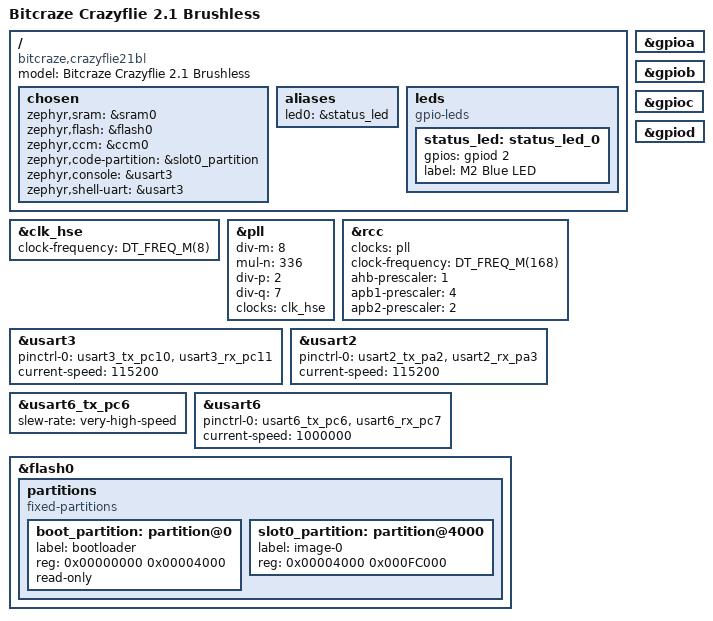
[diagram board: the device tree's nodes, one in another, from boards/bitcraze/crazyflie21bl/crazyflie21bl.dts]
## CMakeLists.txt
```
cmake_minimum_required(VERSION 3.20.0)

# Out-of-tree board definitions (crazyflie21bl).  Must be set before find_package.
list(APPEND BOARD_ROOT ${CMAKE_CURRENT_SOURCE_DIR})

# tapestry-os/dts/bindings/ holds custom DTS bindings (e.g. bitcraze,cf21-motors).
list(APPEND DTS_ROOT ${CMAKE_CURRENT_SOURCE_DIR}/../tapestry-os)

if("${BOARD}" STREQUAL "bbc_microbit_v2")
    set(DTC_OVERLAY_FILE
        ${CMAKE_CURRENT_SOURCE_DIR}/../tapestry-os/boards/bbc_microbit_v2/bbc_microbit_v2.overlay)
elseif("${BOARD}" STREQUAL "crazyflie21bl")
    set(DTC_OVERLAY_FILE
        ${CMAKE_CURRENT_SOURCE_DIR}/../tapestry-os/boards/crazyflie21bl/crazyflie21bl.overlay)
elseif("${BOARD}" STREQUAL "apollo510_evb")
    set(DTC_OVERLAY_FILE
        ${CMAKE_CURRENT_SOURCE_DIR}/../tapestry-os/boards/apollo510_evb/apollo510_evb.overlay)
elseif("${BOARD}" STREQUAL "apollo330mP_evb")
    set(DTC_OVERLAY_FILE
        ${CMAKE_CURRENT_SOURCE_DIR}/../tapestry-os/boards/apollo330mP_evb/apollo330mP_evb.overlay)
elseif("${BOARD}" STREQUAL "ek_ra8d1")
    # Adds only a tapestry,gossip-uart chosen node pointing at UART3, so the
    # RA8D1 can join a wired gossip bus.  Inert in the default Ethernet/UDP
    # build — nothing reads the node unless transceiver_uart.c is compiled in.
    set(DTC_OVERLAY_FILE
        ${CMAKE_CURRENT_SOURCE_DIR}/../tapestry-os/boards/ek_ra8d1/ek_ra8d1.overlay)
endif()

# Apollo510 EVB: make `west flash` reliable.
#
# The Apollo510 is a secure part whose bootloader must run to completion after
# reset.  J-Link's default reset races it: the runner's generated script goes
# `r` straight into `loadfile` with no `halt` between, so the flash loader can
# start while the bootloader is still running.  Measured on hardware
# 2026-08-25: 2 failures in 4 runs, each aborting after "Programming flash
# [100%] Done" and leaving a HALF-WRITTEN image that boots and then hard-faults
# — a failure that reads convincingly as a firmware bug.
#
# Reset type 2 fixes it: 5 clean runs versus 2 failures in 4 with the default
# reset.  Under the old rate a clean run of 5 had roughly a 3% chance, so the
# improvement is real — though 5 trials cannot prove a race never fires.  west
# exits non-zero on failure, so a bad flash is always visible at the shell.
# `--speed 500` was tried and did not help.
#
# Injected via the BOARD_RUNNER_ARGS_<runner> cache variable, which
# board_finalize_runner_args() appends last of all (so it wins over the board's
# own args).  The documented app_set_runner_args() macro hook was tried first
# and did not take effect on Zephyr 4.4.0-rc1 — board_finalize_runner_args()
# demonstrably ran (its --dt-flash=y reached runners.yaml) but did not see the
# macro.  Unexplained; the cache variable is read by the same function two
# lines later and does work.
if("${BOARD}" STREQUAL "apollo510_evb")
    set(BOARD_RUNNER_ARGS_jlink "--reset-type=2" CACHE INTERNAL
        "Ambiq secure-bootloader-safe JLink reset")
endif()
# apollo330mP_evb is excluded: Ambiq's bundled jlink.py runner has no
# --reset-type option and errors on it.

find_package(Zephyr REQUIRED HINTS $ENV{ZEPHYR_BASE})
project(tapestry_hw_element)

set(TAPESTRY_OS_ROOT      ${CMAKE_CURRENT_SOURCE_DIR}/../tapestry-os)
set(TAPESTRY_OS_CSM       ${TAPESTRY_OS_ROOT}/subsys/csm)
set(TAPESTRY_OS_SCR       ${TAPESTRY_OS_ROOT}/subsys/scr)
set(TAPESTRY_OS_TRANSPORT ${TAPESTRY_OS_ROOT}/subsys/transport)
set(TAPESTRY_OS_BSE       ${TAPESTRY_OS_ROOT}/subsys/bse)
set(TAPESTRY_OS_CHOREO    ${TAPESTRY_OS_ROOT}/subsys/choreo)
set(TAPESTRY_OS_RUNTIME   ${TAPESTRY_OS_ROOT}/subsys/runtime)
set(TAPESTRY_OS_BOARDS    ${TAPESTRY_OS_ROOT}/boards)
set(TAPESTRY_SDK          ${CMAKE_CURRENT_SOURCE_DIR}/../sdk)

# Core L2 runtime + L4/L5 stack + L6 BSE stub + L7 SDK stub + transport.
target_sources(app PRIVATE
    src/main.c
    ${TAPESTRY_OS_RUNTIME}/runtime.c
    ${TAPESTRY_OS_RUNTIME}/power.c
    ${TAPESTRY_OS_CSM}/world_model.c
    ${TAPESTRY_OS_CSM}/facts.c
    ${TAPESTRY_OS_SCR}/scr.c
    ${TAPESTRY_OS_BSE}/bse.c
    ${TAPESTRY_OS_CHOREO}/choreo.c
    ${TAPESTRY_OS_TRANSPORT}/transport.c
    ${TAPESTRY_OS_TRANSPORT}/gossip.c
)

# UDP transceiver + network bring-up — ESP32 and RA8D1 only.
if(CONFIG_NETWORKING)
    target_sources(app PRIVATE
        ${TAPESTRY_OS_TRANSPORT}/transceiver_udp.c
        ${TAPESTRY_OS_TRANSPORT}/net_init.c
    )
endif()

# BLE transceiver — ESP32 (bridge) and micro:bit.
if(CONFIG_BT)
    target_sources(app PRIVATE ${TAPESTRY_OS_TRANSPORT}/transceiver_ble.c)
endif()

# Stub transceiver backends (compiled when the matching Kconfig symbol is set
# by a board overlay; not active in any current build).
if(CONFIG_TAPESTRY_TRANSCEIVER_ACOUSTIC)
    target_sources(app PRIVATE ${TAPESTRY_OS_TRANSPORT}/transceiver_acoustic.c)
endif()
if(CONFIG_TAPESTRY_TRANSCEIVER_OPTICAL)
    target_sources(app PRIVATE ${TAPESTRY_OS_TRANSPORT}/transceiver_optical.c)
endif()
if(CONFIG_TAPESTRY_TRANSCEIVER_CHEMICAL)
    target_sources(app PRIVATE ${TAPESTRY_OS_TRANSPORT}/transceiver_chemical.c)
endif()
if(CONFIG_TAPESTRY_TRANSCEIVER_SYSLINK)
    target_sources(app PRIVATE ${TAPESTRY_OS_TRANSPORT}/transceiver_syslink_p2p.c)
endif()

# Wired serial gossip bus — the only medium available to radio-less boards
# (Apollo510 EVB).  Board-agnostic: needs a spare interrupt-driven UART and a
# `tapestry,gossip-uart` chosen node in the board overlay.
if(CONFIG_TAPESTRY_TRANSCEIVER_UART)
    target_sources(app PRIVATE ${TAPESTRY_OS_TRANSPORT}/transceiver_uart.c)
endif()

# CF2.1 early IWDG kick — must be compiled unconditionally so it runs even in
# minimal blink-test builds (CONFIG_PWM=n).  The Bitcraze bootloader arms the
# IWDG before jumping to us; without this, the watchdog fires within ~100-353ms.
#
# CF2.1 CRTP log backend — sends Zephyr LOG_* output as syslink console packets
# over USART6 to the nRF51 co-processor; crazyflie_console.py receives them via radio.
# Compiled only when CONFIG_LOG=y (i.e. the log subsystem is present).
# cf21bl_syslink_tx.c (the shared USART6 TX mutex) is compiled unconditionally
# alongside it so any combination of USART6 writers (console, PM, syslink P2P
# transport) can be linked together safely.
if("${BOARD}" STREQUAL "crazyflie21bl")
    target_sources(app PRIVATE
        ${TAPESTRY_OS_BOARDS}/crazyflie21bl/cf21bl_iwdg.c
        ${TAPESTRY_OS_BOARDS}/crazyflie21bl/cf21bl_syslink_tx.c)
    if(CONFIG_LOG)
        target_sources(app PRIVATE ${TAPESTRY_OS_BOARDS}/crazyflie21bl/cf21bl_crtp_log.c)
    endif()
endif()

# Substrate: CF2.1 brushless on crazyflie21bl, Cutebot on micro:bit,
# LED/button status output on apollo510_evb, null elsewhere.
#
# Boards with a substrate of their own are matched by NAME before the
# CONFIG_* heuristics below.  Those heuristics infer a substrate from which
# buses a board happens to enable, which is only sound while every such board
# has exactly one plausible substrate — apollo510_evb breaks that (it has no
# actuators at all, and enabling I2C or PWM on it for an unrelated reason
# would silently select the Cutebot or Crazyflie driver).
#
# Within the heuristics, PWM must be checked before I2C: the CF21 stabilizer
# uses both (PWM for motors, I2C for the BMI088 IMU), so checking I2C first
# would wrongly select the Cutebot path.
if("${BOARD}" STREQUAL "apollo510_evb" OR "${BOARD}" STREQUAL "apollo330mP_evb")
    # Shared LED/button substrate — entirely devicetree-driven (led0..led2, sw0),
    # so one implementation serves both Ambiq EVBs.
    target_sources(app PRIVATE
        ${TAPESTRY_OS_BOARDS}/ambiq_common/substrate_ambiq_evb.c)
    if("${BOARD}" STREQUAL "apollo510_evb" AND CONFIG_TAPESTRY_AP510_PIN_FINDER)
        target_sources(app PRIVATE
            ${TAPESTRY_OS_BOARDS}/apollo510_evb/ap510_pin_finder.c)
    endif()
elseif(CONFIG_PWM)
    target_sources(app PRIVATE
        ${TAPESTRY_OS_BOARDS}/crazyflie21bl/substrate_crazyflie21bl.c
        ${TAPESTRY_OS_BOARDS}/crazyflie21bl/crazyflie21bl.c
    )
    if(CONFIG_CF21BL_STABILIZER)
        target_sources(app PRIVATE
            ${TAPESTRY_OS_BOARDS}/crazyflie21bl/cf21bl_stabilizer.c
            ${TAPESTRY_OS_BOARDS}/crazyflie21bl/cf21bl_imu.c
        )
    endif()
elseif(CONFIG_I2C)
    target_sources(app PRIVATE
        ${TAPESTRY_OS_BOARDS}/bbc_microbit_v2/substrate_cutebot.c
        ${TAPESTRY_OS_BOARDS}/bbc_microbit_v2/cutebot.c
    )
else()
    target_sources(app PRIVATE ${TAPESTRY_OS_BOARDS}/substrate_null.c)
endif()

target_include_directories(app PRIVATE
    ${TAPESTRY_OS_ROOT}/include                    # <tapestry/csm.h>, <tapestry/scr.h>, <tapestry/transport.h>, <tapestry/substrate.h>, <tapestry/bse.h>, <tapestry/runtime.h>
    ${TAPESTRY_SDK}/include                        # <tapestry/choreo.h>
    ${TAPESTRY_OS_CSM}                             # world_model.c; types via <tapestry/csm.h>
    ${TAPESTRY_OS_SCR}                             # scr.h internals
    ${TAPESTRY_OS_RUNTIME}                         # power.h (internal)
    ${TAPESTRY_OS_TRANSPORT}                       # gossip.h, transceiver_ble.h, transceiver_udp.h, net_init.h
    ${TAPESTRY_OS_BOARDS}/bbc_microbit_v2          # cutebot.h
    ${TAPESTRY_OS_BOARDS}/crazyflie21bl             # crazyflie21bl_mix.h, crazyflie21bl.h
    src
)

target_link_libraries(app PRIVATE m)
```

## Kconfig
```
# Kconfig — Tapestry hardware element configuration
#
# Values are baked into the firmware at build time via CONFIG_* macros.
# WiFi credentials are sensitive: supply them via a gitignored wifi.conf
# passed with  west build --extra-conf wifi.conf
# (--extra-conf resolves relative to the application directory, not the CWD)

# Pull in all Zephyr Kconfig symbols (NETWORKING, WIFI, LOG, …).
# Without this every standard symbol appears "undefined".
source "Kconfig.zephyr"
rsource "../tapestry-os/subsys/runtime/Kconfig"
rsource "../tapestry-os/subsys/transport/Kconfig"
rsource "../tapestry-os/boards/crazyflie21bl/Kconfig"
rsource "../tapestry-os/boards/apollo510_evb/Kconfig"

config TAPESTRY_ELEMENT_ID
	int "Element ID [0..4]"
	range 0 4
	default 0
	help
	  Unique identity for this physical element. Determines leader
	  election priority (lowest ID wins) and gossip source tagging.
	  Set to 0 for ESP-WROVER-KIT, 1 for EK-RA8D1.

config TAPESTRY_GOSSIP_PORT
	int "UDP port for gossip broadcast/receive"
	default 5000

config TAPESTRY_GOSSIP_BCAST
	string "Gossip broadcast address"
	default "255.255.255.255"
	help
	  Destination address for gossip UDP datagrams.  The limited broadcast
	  (255.255.255.255) is NOT forwarded between WiFi and Ethernet segments
	  by most home routers.  Set this to the subnet directed broadcast
	  (e.g. 192.168.86.255 for a 192.168.86.0/24 network) so that gossip
	  crosses the WiFi/Ethernet boundary.


config TAPESTRY_METRIC_PORT
	int "UDP port for telemetry metrics (unicast to collector)"
	default 5100

config TAPESTRY_ORCH_IP
	string "Telemetry collector IP address"
	default ""
	help
	  IPv4 address of the machine running telemetry/collect.py.
	  Metrics are silently dropped when this is left empty.

config TAPESTRY_QUORUM_MIN
	int "SCR minimum fresh peers for DEGRADED state"
	range 0 4
	default 1

config TAPESTRY_QUORUM_TARGET
	int "SCR minimum fresh peers for HEALTHY state"
	range 0 4
	default 1

if WIFI

config TAPESTRY_WIFI_SSID
	string "WiFi SSID"
	default ""

config TAPESTRY_WIFI_PSK
	string "WiFi pre-shared key (WPA2)"
	default ""

endif # WIFI
```

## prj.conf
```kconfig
# ── Stack / heap ──────────────────────────────────────────────────────────────
CONFIG_MAIN_STACK_SIZE=8192

# ── Floating point ────────────────────────────────────────────────────────────
# Needed explicitly for ESP32 and micro:bit; harmless for RA8D1.
CONFIG_FPU=y

# ── Logging ───────────────────────────────────────────────────────────────────
CONFIG_LOG=y
CONFIG_LOG_DEFAULT_LEVEL=3
CONFIG_PRINTK=y

# Board-specific configs (networking, BLE, I2C) live in boards/<board>.conf
# so each target only pulls in what its hardware supports.
```

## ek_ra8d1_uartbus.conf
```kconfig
# Wired-gossip-bus variant for the Renesas EK-RA8D1.
#
# Overrides the board's default Ethernet/UDP transport (boards/ek_ra8d1.conf)
# so the RA8D1 gossips over a shared serial bus instead — letting it pair
# directly with the radio-less Apollo510 EVB with no host, no LAN, and no
# collector.  A genuinely heterogeneous swarm: Renesas Cortex-M85 talking to
# Ambiq Cortex-M55 over two wires.
#
# Build (from the workspace root):
#   west build -b ek_ra8d1 \
#       --build-dir tapestry/tapestry-scr-hw/build/ra8d1-e1 \
#       tapestry/tapestry-scr-hw \
#       --extra-conf ek_ra8d1_uartbus.conf
#
# The --extra-conf path is resolved relative to the APPLICATION directory
# (tapestry-scr-hw), not the shell CWD — hence the bare filename.
#
# Element ID comes from boards/ek_ra8d1.conf, which already sets 1 — pairing
# with the Apollo510's default of 0.
#
# EXPECTED: this build prints a handful of Kconfig warnings about NET_* symbols
# having unmet dependencies.  They come from the networking block in
# boards/ek_ra8d1.conf, which Zephyr merges before this file and which cannot
# be made conditional.  Harmless — the symbols below win.

# ── Networking OFF ────────────────────────────────────────────────────────────
# Not merely unused: net_connect() ends in k_sem_take(&ip_acquired, K_FOREVER),
# so with networking enabled and no DHCP lease the element blocks forever in
# transport_init() and never reaches its main loop.  It must be off for a
# cable-free bus test.
#
# Turning networking off also switches telemetry from UDP-to-collector back to
# METRIC CSV lines on the console, which is what we want on the bench — and
# matches what the Apollo510 prints.
CONFIG_NETWORKING=n
CONFIG_NET_SOCKETS=n
CONFIG_NET_UDP=n
CONFIG_NET_IPV4=n
CONFIG_NET_DHCPV4=n
CONFIG_NET_L2_ETHERNET=n
CONFIG_NET_ARP=n

# ── Gossip transport: wired serial bus ────────────────────────────────────────
# UART3 (SCI3) is already enabled at 115200 by the stock board DTS; the
# Tapestry overlay only adds the tapestry,gossip-uart chosen node.
CONFIG_SERIAL=y
CONFIG_UART_INTERRUPT_DRIVEN=y
CONFIG_TAPESTRY_TRANSCEIVER_UART=y

# ── Hardware identity ─────────────────────────────────────────────────────────
CONFIG_HWINFO=y
```

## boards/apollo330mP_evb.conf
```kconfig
# Board overlay for the Ambiq Apollo330M Plus EVB (Apollo330P / Cortex-M55)
#
# Unlike the Apollo510 EVB this part has an on-die BLE controller reached over
# an HCI IPC channel (zephyr,bt-hci = &bt_hci_ipc0 in the board DTS), so it can
# gossip over BLE, over the wired serial bus, or both at once.  Both are
# enabled here: the wired bus pairs it with the Apollo510 EVB, and BLE pairs it
# with any Tapestry BLE element (micro:bit, ESP32).
#
# This board lives in Ambiq's Zephyr distribution, not upstream Zephyr — see
# tapestry-os/boards/apollo330mP_evb/README.md for the workspace.
#
# Build (from the workspace root):
#   west build -b apollo330mP_evb \
#       --build-dir tapestry/tapestry-scr-hw/build/ap330-e1 \
#       tapestry/tapestry-scr-hw -- -DCONFIG_TAPESTRY_ELEMENT_ID=1

# ── Floating point ────────────────────────────────────────────────────────────
CONFIG_FPU=y
CONFIG_FPU_SHARING=y

# ── Gossip transport: wired serial bus ────────────────────────────────────────
# UART1 is brought up as the bus by the Tapestry overlay, which also sets the
# tapestry,gossip-uart chosen node the transceiver reads.
CONFIG_SERIAL=y
CONFIG_UART_INTERRUPT_DRIVEN=y
CONFIG_TAPESTRY_TRANSCEIVER_UART=y

# ── Gossip transport: BLE ─────────────────────────────────────────────────────
# transceiver_ble.c registers alongside the wired bus; gossip_drain merges
# frames from both.  Comment this block out for a wired-only element.
CONFIG_BT=y
CONFIG_BT_OBSERVER=y
CONFIG_BT_BROADCASTER=y
# Peers on current main (micro:bit, ESP32) advertise the gossip frame with
# extended advertising; the scanner only receives those reports with this on.
CONFIG_BT_EXT_ADV=y
# Two advertising sets: state gossip and shared facts (transceiver_ble.c).
CONFIG_BT_EXT_ADV_MAX_ADV_SET=2
CONFIG_BT_DEVICE_NAME="tapestry-ap330"
CONFIG_BT_RX_STACK_SIZE=4096
CONFIG_SYSTEM_WORKQUEUE_STACK_SIZE=4096

# ── Hardware identity ─────────────────────────────────────────────────────────
CONFIG_HWINFO=y

# ── GPIO (LEDs + buttons for the L1 substrate) ────────────────────────────────
CONFIG_GPIO=y

# ── Element identity ──────────────────────────────────────────────────────────
# Override at build time with: -- -DCONFIG_TAPESTRY_ELEMENT_ID=N
# Defaults to 1 so it pairs with the Apollo510 EVB's default of 0.
CONFIG_TAPESTRY_ELEMENT_ID=1
```

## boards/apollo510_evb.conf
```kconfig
# Board overlay for the Ambiq Apollo510 EVB (Apollo510 / Cortex-M55)
# Radio-less swarm element: gossip over a wired serial bus, status on the
# three on-board LEDs, telemetry as METRIC CSV lines over the UART0 console.
#
# Build (from the workspace root):
#   west build -b apollo510_evb \
#       --build-dir tapestry/tapestry-scr-hw/build/ap510-e0 \
#       tapestry/tapestry-scr-hw -- -DCONFIG_TAPESTRY_ELEMENT_ID=0
#   west flash --build-dir tapestry/tapestry-scr-hw/build/ap510-e0
#
# Console: UART0, 115200 8N1, on the EVB's J-Link USB VCOM port.
#   minicom -D /dev/ttyACM0 -b 115200
#
# See tapestry-os/boards/apollo510_evb/README.md for bus wiring.

# ── Floating point ────────────────────────────────────────────────────────────
# The apollo5x SoC Kconfig selects CPU_HAS_FPU but does not turn CONFIG_FPU on.
# FPU_SHARING saves/restores FPU registers on context switches — required
# because float-touching code runs in main, the system workqueue, and the
# gossip stats work handler.
CONFIG_FPU=y
CONFIG_FPU_SHARING=y

# ── Gossip transport: wired serial bus ────────────────────────────────────────
# The Apollo510 has no radio on-die, so elements gossip over a shared UART
# bus.  UART2 is brought up as that bus by the Tapestry overlay
# (tapestry-os/boards/apollo510_evb/apollo510_evb.overlay), which also sets
# the `tapestry,gossip-uart` chosen node the transceiver reads.
#
# CONFIG_UART_INTERRUPT_DRIVEN is already set by the board's own defconfig.
CONFIG_SERIAL=y
CONFIG_UART_INTERRUPT_DRIVEN=y
CONFIG_TAPESTRY_TRANSCEIVER_UART=y

# ── Hardware identity ─────────────────────────────────────────────────────────
# Feeds the auto-ID nonce (CHIPID0/CHIPID1/trim revision via hwinfo_ambiq).
# Not required by this element — it takes its ID from Kconfig below — but
# cheap, and applications that call transport_negotiate_id() need it.
CONFIG_HWINFO=y

# ── GPIO (LEDs + buttons for the L1 substrate) ────────────────────────────────
CONFIG_GPIO=y

# ── Element identity ──────────────────────────────────────────────────────────
# Override at build time with: -- -DCONFIG_TAPESTRY_ELEMENT_ID=N
CONFIG_TAPESTRY_ELEMENT_ID=0

# ── Power management ──────────────────────────────────────────────────────────
# The board defconfig enables CONFIG_PM / PM_DEVICE / PM_DEVICE_RUNTIME and the
# SoC devicetree offers suspend-to-idle and suspend-to-ram.  Left on, and
# CONFIRMED on hardware 2026-08-25: transceiver_uart.c takes a pm_policy lock on
# PM_STATE_SUSPEND_TO_RAM at init so the gossip UART keeps its clock between
# cycles, while the shallower idle state stays available.  Loopback gossip runs
# clean with PM enabled — no special build flag is needed.
#
# If gossip RX ever goes lossy on a larger bus, CONFIG_PM=n is still the first
# bisect: it rules the policy lock in or out in one build.
```

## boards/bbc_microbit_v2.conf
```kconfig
# Board overlay for BBC micro:bit V2 (nRF52833 / Cortex-M4F)
# BLE swarm element with Cutebot Mini motor and LED output.
#
# No networking stack — gossip travels over BLE advertising instead.
# Telemetry is emitted as METRIC CSV lines over USB serial (115200 baud).
#
# The nRF52833 has a hardware FPU but Zephyr does not enable it by default.
# FPU_SHARING saves/restores FPU registers on context switches.

# ── Floating point ────────────────────────────────────────────────────────────
CONFIG_FPU=y
CONFIG_FPU_SHARING=y

# ── Bluetooth ─────────────────────────────────────────────────────────────────
# CONFIG_BT_EXT_ADV: required since the gossip frame (wire.h v3, 42 bytes)
# no longer fits legacy advertising's 31-byte payload — see
# transceiver_ble.c's header comment.
CONFIG_BT=y
CONFIG_BT_OBSERVER=y
CONFIG_BT_BROADCASTER=y
CONFIG_BT_EXT_ADV=y

# Controller advertising/scan BUFFERS are separate knobs from the
# extended-advertising feature itself and both default to 31 (the legacy
# payload size).  Left at the default, bt_le_ext_adv_set_data() fails -EDOM
# for every 48-byte wire.h v3 frame and no gossip is ever transmitted — the
# advertiser still starts cleanly, so the only symptom is that every element
# sees zero peers.  See examples/cutebot-formation/boards/bbc_microbit_v2.conf
# for the full write-up (2026-08-24).
CONFIG_BT_CTLR_ADV_DATA_LEN_MAX=64
CONFIG_BT_CTLR_SCAN_DATA_LEN_MAX=64
# Two advertising sets: state gossip and shared facts (transceiver_ble.c).
CONFIG_BT_EXT_ADV_MAX_ADV_SET=2
CONFIG_BT_DEVICE_NAME="tapestry"
CONFIG_BT_RX_STACK_SIZE=4096
CONFIG_SYSTEM_WORKQUEUE_STACK_SIZE=4096

# ── I2C (Cutebot) ─────────────────────────────────────────────────────────────
CONFIG_I2C=y
CONFIG_I2C_GPIO=y

# ── Element identity ──────────────────────────────────────────────────────────
# Override at build time with: -- -DCONFIG_TAPESTRY_ELEMENT_ID=N
CONFIG_TAPESTRY_ELEMENT_ID=0
```

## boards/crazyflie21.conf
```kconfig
# Board overlay for Bitcraze Crazyflie 2.1 brushless (STM32F405 / Cortex-M4F)
# BLE swarm element with brushless ESC output via TIM2 PWM.
#
# Build:
#   west build -b crazyflie21 tapestry/tapestry-scr-hw
#
# The Crazyflie 2.1 has an nRF51822 radio co-processor connected over UART.
# Full BLE gossip transport requires a UART-to-BLE bridge driver; that work
# is deferred until the board DTS is finalised.  The transport stubs compile
# and link cleanly; gossip simply produces no packets until the bridge lands.

# ── Floating point ────────────────────────────────────────────────────────────
CONFIG_FPU=y
CONFIG_FPU_SHARING=y

# ── PWM (brushless motor ESCs via TIM2) ───────────────────────────────────────
CONFIG_PWM=y

# ── Bluetooth (nRF51822 co-processor via USART6 HCI) ─────────────────────────
#
# PREREQUISITE: reflash the nRF51822 with HCI firmware before enabling.
# The factory radio firmware is not HCI-compatible.
#
# Once nRF51 runs HCI firmware, uncomment all lines below and rebuild.
# The USART6 node (PC6/PC7, 1 Mbps) is already enabled in the overlay.
#
# CONFIG_BT=y
# CONFIG_BT_HCI_UART=y
# CONFIG_BT_OBSERVER=y
# CONFIG_BT_BROADCASTER=y
# CONFIG_BT_DEVICE_NAME="tapestry-cf21"
# CONFIG_BT_RX_STACK_SIZE=4096
# CONFIG_SYSTEM_WORKQUEUE_STACK_SIZE=4096

# ── Element identity ──────────────────────────────────────────────────────────
# Override at build time with: -- -DCONFIG_TAPESTRY_ELEMENT_ID=N
CONFIG_TAPESTRY_ELEMENT_ID=0
```

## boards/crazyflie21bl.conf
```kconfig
# Board overlay for Bitcraze Crazyflie 2.1 brushless (STM32F405 / Cortex-M4F)
# BLE swarm element with brushless ESC output via TIM2 PWM.
#
# Build:
#   west build -b crazyflie21bl tapestry/tapestry-scr-hw -- -DCONFIG_PWM=n
#
# Console: USART3 on PC10 (TX) / PC11 (RX), 115200 baud.
# Connect a 3.3 V USB-serial adapter: white (RX) → PC10, green (TX) → PC11, GND.
# On Linux: minicom -D /dev/ttyUSB0 -b 115200

# ── Floating point ────────────────────────────────────────────────────────────
CONFIG_FPU=y
CONFIG_FPU_SHARING=y


# ── PWM (brushless motor ESCs via TIM2) ───────────────────────────────────────
CONFIG_PWM=y

# ── Bluetooth (nRF51822 co-processor via USART6 HCI) ─────────────────────────
#
# PREREQUISITE: reflash the nRF51822 with HCI firmware before enabling.
# The factory radio firmware is not HCI-compatible.
#
# Once nRF51 runs HCI firmware, uncomment all lines below and rebuild.
# The USART6 node (PC6/PC7, 1 Mbps) is already enabled in the overlay.
#
# CONFIG_BT=y
# CONFIG_BT_HCI_UART=y
# CONFIG_BT_OBSERVER=y
# CONFIG_BT_BROADCASTER=y
# CONFIG_BT_DEVICE_NAME="tapestry-cf21"
# CONFIG_BT_RX_STACK_SIZE=4096
# CONFIG_SYSTEM_WORKQUEUE_STACK_SIZE=4096

# ── Element identity ──────────────────────────────────────────────────────────
# Override at build time with: -- -DCONFIG_TAPESTRY_ELEMENT_ID=N
CONFIG_TAPESTRY_ELEMENT_ID=0

# Logging — required for cf21bl_crtp_log.c to be compiled and activated.
CONFIG_LOG=y
CONFIG_LOG_BACKEND_SHOW_COLOR=n

# USB CDC ACM console: attempted, blocked by what looked like a PLL_Q clock
# issue. Likely same root cause as the APB1/USART3 baud mismatch — &clk_hse
# in the DTS assumed a 40 MHz TCXO, but the stock firmware (HSE_VALUE=8000000,
# PLL_M=8, HSEBYP cleared) implies an 8 MHz crystal. DTS now corrected to
# 8 MHz / div-m=8; revisit USB CDC once USART3 is confirmed working at the
# corrected clock.
```

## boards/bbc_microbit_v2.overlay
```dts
/* Hardware pin configuration lives with the L1 board support package. */
#include "../../tapestry-os/boards/bbc_microbit_v2/bbc_microbit_v2.overlay"
```

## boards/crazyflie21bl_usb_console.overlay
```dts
/*
 * crazyflie21bl_usb_console.overlay — USB CDC ACM console retry
 *
 * Switches the Zephyr console/shell from the (now-confirmed-working) wired
 * USART3 to USB CDC ACM over the STM32F405's OTG_FS peripheral on PA11/PA12.
 *
 * Pin assignment (PA11=DM, PA12=DP, AF10) confirmed from the stock Bitcraze
 * firmware's USB_OTG_BSP_Init() (crazyflie-firmware/src/hal/src/usb_bsp.c) —
 * VBUS sensing is intentionally NOT wired (matches stock firmware, which
 * leaves the VBUS GPIO_InitStructure commented out); omitting
 * usb_otg_fs_vbus_pa9 from pinctrl-0 makes the Zephyr STM32 USB driver
 * disable VBUS sensing automatically (see USB_VBUS_SENSING in usb_dc_stm32.c).
 *
 * USB's 48 MHz clock comes from the same PLL_Q=7 path whose baud-rate-style
 * symptoms were caused by the wrong &clk_hse frequency (see crazyflie21bl.dts);
 * this overlay exists to test whether that fix also unblocks USB.
 *
 * Build:
 *   west build -p always -b crazyflie21bl tapestry/tapestry-scr-hw -- \
 *     -DCONFIG_PWM=n \
 *     -DEXTRA_DTC_OVERLAY_FILE=boards/crazyflie21bl_usb_console.overlay \
 *     -DCONFIG_USB_DEVICE_STACK_NEXT=y \
 *     -DCONFIG_CDC_ACM_SERIAL_INITIALIZE_AT_BOOT=y \
 *     -DCONFIG_CDC_ACM_SERIAL_PRODUCT_STRING="\"Tapestry CF21 console\""
 *
 * Read:
 *   minicom -D /dev/ttyACM0   (CDC ACM is rate-less; any baud setting works)
 */

/ {
	chosen {
		zephyr,console = &cdc_acm_uart0;
		zephyr,shell-uart = &cdc_acm_uart0;
	};
};

zephyr_udc0: &usbotg_fs {
	pinctrl-0 = <&usb_otg_fs_dm_pa11 &usb_otg_fs_dp_pa12>;
	pinctrl-names = "default";
	status = "okay";

	cdc_acm_uart0: cdc_acm_uart0 {
		compatible = "zephyr,cdc-acm-uart";
	};
};
```

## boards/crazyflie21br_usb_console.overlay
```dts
/*
 * crazyflie21br_usb_console.overlay — USB CDC ACM console retry
 *
 * Switches the Zephyr console/shell from the (now-confirmed-working) wired
 * USART3 to USB CDC ACM over the STM32F405's OTG_FS peripheral on PA11/PA12.
 *
 * Pin assignment (PA11=DM, PA12=DP, AF10) confirmed from the stock Bitcraze
 * firmware's USB_OTG_BSP_Init() (crazyflie-firmware/src/hal/src/usb_bsp.c) —
 * VBUS sensing is intentionally NOT wired (matches stock firmware, which
 * leaves the VBUS GPIO_InitStructure commented out); omitting
 * usb_otg_fs_vbus_pa9 from pinctrl-0 makes the Zephyr STM32 USB driver
 * disable VBUS sensing automatically (see USB_VBUS_SENSING in usb_dc_stm32.c).
 *
 * USB's 48 MHz clock comes from the same PLL_Q=7 path whose baud-rate-style
 * symptoms were caused by the wrong &clk_hse frequency (see crazyflie21br.dts);
 * this overlay exists to test whether that fix also unblocks USB.
 *
 * Build:
 *   west build -p always -b crazyflie21br tapestry/tapestry-scr-hw -- \
 *     -DCONFIG_PWM=n \
 *     -DEXTRA_DTC_OVERLAY_FILE=boards/crazyflie21br_usb_console.overlay \
 *     -DCONFIG_USB_DEVICE_STACK_NEXT=y \
 *     -DCONFIG_CDC_ACM_SERIAL_INITIALIZE_AT_BOOT=y \
 *     -DCONFIG_CDC_ACM_SERIAL_PRODUCT_STRING="\"Tapestry CF21 console\""
 *
 * Read:
 *   minicom -D /dev/ttyACM0   (CDC ACM is rate-less; any baud setting works)
 */

/ {
	chosen {
		zephyr,console = &cdc_acm_uart0;
		zephyr,shell-uart = &cdc_acm_uart0;
	};
};

zephyr_udc0: &usbotg_fs {
	pinctrl-0 = <&usb_otg_fs_dm_pa11 &usb_otg_fs_dp_pa12>;
	pinctrl-names = "default";
	status = "okay";

	cdc_acm_uart0: cdc_acm_uart0 {
		compatible = "zephyr,cdc-acm-uart";
	};
};
```

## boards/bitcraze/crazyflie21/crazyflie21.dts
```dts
/*
 * crazyflie21.dts — Zephyr board DTS for Bitcraze Crazyflie 2.1 Brushless
 *
 * MCU:   STM32F405RGT6 (Cortex-M4F, 168 MHz, 1 MB flash, 192 KB SRAM)
 * Clock: 40 MHz TCXO (hse-bypass) → PLL → 168 MHz SYSCLK
 *
 * Pin assignments marked TODO must be verified against the CF2.1 brushless
 * schematic before flashing real hardware:
 *   https://www.bitcraze.io/documentation/hardware/crazyflie_2_1/
 *
 * Motor PWM and the nRF51 HCI UART are configured in the app overlay
 * (tapestry-os/boards/crazyflie21/crazyflie21.overlay).
 */

/dts-v1/;
#include <st/f4/stm32f405Xg.dtsi>
#include <st/f4/stm32f405rgtx-pinctrl.dtsi>
#include <zephyr/dt-bindings/gpio/gpio.h>

/ {
	model = "Bitcraze Crazyflie 2.1 Brushless";
	compatible = "bitcraze,crazyflie21";

	chosen {
		zephyr,sram   = &sram0;
		zephyr,flash  = &flash0;
		zephyr,ccm    = &ccm0;
		zephyr,console    = &usart1;
		zephyr,shell-uart = &usart1;
	};

	aliases {
		led0 = &status_led;
	};

	/*
	 * Single status LED driven by GPIO.
	 * TODO: verify PC1 against the CF2.1 brushless schematic.
	 *       On the stock CF2.1, status LEDs are on PC0/PC1/PC2/PC3;
	 *       PC1 is used here as the primary indicator.
	 */
	leds {
		compatible = "gpio-leds";
		status_led: status_led_0 {
			gpios = <&gpioc 1 GPIO_ACTIVE_HIGH>;
			label = "Status LED";
		};
	};
};

/* ── Clocks ──────────────────────────────────────────────────────────────── */

&clk_hse {
	/*
	 * CF2.1 uses a 40 MHz VCTCXO oscillator (bypass mode — no crystal).
	 * PLL: VCO_in = 40/40 = 1 MHz, VCO_out = 336 MHz
	 *      SYSCLK = 336/2 = 168 MHz, USB = 336/7 = 48 MHz
	 */
	hse-bypass;
	clock-frequency = <DT_FREQ_M(40)>;
	status = "okay";
};

&pll {
	div-m = <40>;
	mul-n = <336>;
	div-p = <2>;
	div-q = <7>;
	clocks = <&clk_hse>;
	status = "okay";
};

&rcc {
	clocks        = <&pll>;
	clock-frequency = <DT_FREQ_M(168)>;
	ahb-prescaler = <1>;
	apb1-prescaler = <4>;   /* APB1 max 42 MHz */
	apb2-prescaler = <2>;   /* APB2 max 84 MHz */
};

/* ── Debug / console UART ────────────────────────────────────────────────── */

/*
 * USART1 on PA9/PA10 is routed to the expansion port and is used as the
 * Zephyr console / shell.
 * TODO: verify PA9/PA10 availability on the brushless variant.
 */
&usart1 {
	pinctrl-0 = <&usart1_tx_pa9 &usart1_rx_pa10>;
	pinctrl-names = "default";
	current-speed = <115200>;
	status = "okay";
};

/* ── nRF51822 BLE radio co-processor ────────────────────────────────────── */

/*
 * The nRF51822 is connected to the STM32F405 via USART6 (PC6/PC7).
 * Zephyr BT_HCI_UART uses this UART once the nRF51 is reflashed with
 * standard HCI firmware (see PORTING.md / crazyflie21.conf TODO).
 * Disabled here; the app overlay enables it when CONFIG_BT_HCI_UART=y.
 *
 * TODO: verify USART6 pin assignment from CF2.1 schematic.
 *       Alternate candidate: USART3 on PB10/PB11 (conflicts with TIM2_CH4).
 */
&usart6 {
	pinctrl-0 = <&usart6_tx_pc6 &usart6_rx_pc7>;
	pinctrl-names = "default";
	current-speed = <1000000>;   /* nRF51 HCI UART: 1 Mbps */
	status = "disabled";
};

/* ── GPIO banks ───────────────────────────────────────────────────────────── */

&gpioa { status = "okay"; };
&gpiob { status = "okay"; };
&gpioc { status = "okay"; };
```

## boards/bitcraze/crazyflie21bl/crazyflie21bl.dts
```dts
/*
 * crazyflie21bl.dts — Zephyr board DTS for Bitcraze Crazyflie 2.1 Brushless
 *
 * MCU:   STM32F405RGT6 (Cortex-M4F, 168 MHz, 1 MB flash, 192 KB SRAM)
 * Clock: 8 MHz HSE crystal → PLL (M=8,N=336,P=2,Q=7) → 168 MHz SYSCLK / 48 MHz USB
 *
 * Console: USART3 on PC10 (TX) / PC11 (RX), 115200 baud.
 * Connect a 3.3 V USB-serial adapter: white (adapter RX) → PC10, green (adapter TX) → PC11, GND.
 *
 * Motor PWM and the nRF51 HCI UART are configured in the app overlay
 * (tapestry-os/boards/crazyflie21bl/crazyflie21bl.overlay).
 */

/dts-v1/;
#include <st/f4/stm32f405Xg.dtsi>
#include <st/f4/stm32f405rgtx-pinctrl.dtsi>
#include <zephyr/dt-bindings/gpio/gpio.h>

/ {
	model = "Bitcraze Crazyflie 2.1 Brushless";
	compatible = "bitcraze,crazyflie21bl";

	chosen {
		zephyr,sram           = &sram0;
		zephyr,flash          = &flash0;
		zephyr,ccm            = &ccm0;
		zephyr,code-partition = &slot0_partition;
		zephyr,console        = &usart3;
		zephyr,shell-uart     = &usart3;
	};

	aliases {
		led0 = &status_led;
	};

	/*
	 * PD2 = LED_BLUE_L — M2 arm blue LED, active-high (STM32 sources current).
	 * This is the only STM32-GPIO-controlled LED visible to the user on the
	 * CF2.1 brushless; there are no LEDs on the main board.
	 *
	 * Main board net names for reference (not routed to visible LEDs):
	 *   LED_RED_L=PC0, LED_GREEN_L=PC1, LED_GREEN_R=PC2, LED_RED_R=PC3.
	 */
	leds {
		compatible = "gpio-leds";
		status_led: status_led_0 {
			gpios = <&gpiod 2 GPIO_ACTIVE_HIGH>;
			label = "M2 Blue LED";
		};
	};
};

/* ── Clocks ──────────────────────────────────────────────────────────────── */

&clk_hse {
	/*
	 * 8 MHz HSE crystal (not bypassed) — matches the stock Bitcraze
	 * firmware's HSE_VALUE=8000000 / PLL_M=8 (system_stm32f4xx.c), which
	 * also explicitly clears HSEBYP before enabling HSE.  No "TCXO"/"40 MHz"
	 * reference exists anywhere in that firmware tree; the previous 40 MHz
	 * bypass assumption produced a ~0.2 MHz PLL input, far outside the
	 * STM32F405's valid 0.95-2.1 MHz PLL input range.
	 *
	 * PLL: VCO_in = 8/8 = 1 MHz, VCO_out = 336 MHz
	 *      SYSCLK = 336/2 = 168 MHz, USB = 336/7 = 48 MHz
	 */
	clock-frequency = <DT_FREQ_M(8)>;
	status = "okay";
};

&pll {
	div-m = <8>;
	mul-n = <336>;
	div-p = <2>;
	div-q = <7>;
	clocks = <&clk_hse>;
	status = "okay";
};

&rcc {
	clocks        = <&pll>;
	clock-frequency = <DT_FREQ_M(168)>;
	ahb-prescaler = <1>;
	/* Canonical STM32F405 168 MHz tree (matches stock firmware): APB1 max
	 * 42 MHz needs /4, APB2 max 84 MHz needs /2.  Earlier debugging set
	 * these to <1>/<1> while chasing a clock mismatch that turned out to
	 * be the wrong &clk_hse frequency (see &clk_hse comment) — with that
	 * fixed, the textbook /4 and /2 prescalers should produce correct
	 * UART baud rates again. */
	apb1-prescaler = <4>;   /* APB1 = 168/4 = 42 MHz */
	apb2-prescaler = <2>;   /* APB2 = 168/2 = 84 MHz */
};

/* ── Console UART ────────────────────────────────────────────────────────── */

/*
 * USART3 on PC10 (TX) / PC11 (RX), 115200 baud.
 * Connect a 3.3 V USB-serial adapter: white (RX) → PC10, green (TX) → PC11, GND.
 */
&usart3 {
	pinctrl-0 = <&usart3_tx_pc10 &usart3_rx_pc11>;
	pinctrl-names = "default";
	current-speed = <115200>;
	status = "okay";
};

&usart2 {
	pinctrl-0 = <&usart2_tx_pa2 &usart2_rx_pa3>;
	pinctrl-names = "default";
	current-speed = <115200>;
	status = "okay";
};

/* ── nRF51822 BLE radio co-processor ────────────────────────────────────── */

/*
 * The nRF51822 is connected to the STM32F405 via USART6 (PC6/PC7).
 * PC6 = STM32 TX (NRF_RX net), PC7 = STM32 RX (NRF_TX net).
 * Pin assignment verified against CF2.1 Brushless schematic Rev.G.
 *
 * Enabled here so that all builds (app and tests) can use USART6 for
 * CRTP syslink console output (cf21bl_crtp_log.c).  The nRF51 factory
 * firmware forwards CRTP console packets over 2.4 GHz radio to
 * crazyradio2; crazyflie_console.py receives them on the host.
 *
 * When the nRF51 is reflashed with HCI firmware for BLE, uncomment
 * CONFIG_BT_HCI_UART in tapestry-scr-hw/boards/crazyflie21bl.conf and
 * disable cf21bl_crtp_log.c (the two uses of USART6 are mutually exclusive).
 */
/* Raise PC6 (USART6_TX) slew rate from Zephyr's default 2 MHz low-speed to
 * very-high-speed (100 MHz).  The CF firmware uses GPIO_Speed_25MHz; without
 * at least medium speed, the 1 Mbps USART transitions take ~250 ns (25% of a
 * bit period) and the nRF51 cannot reliably detect the start bit. */
&usart6_tx_pc6 {
	slew-rate = "very-high-speed";
};

&usart6 {
	pinctrl-0 = <&usart6_tx_pc6 &usart6_rx_pc7>;
	pinctrl-names = "default";
	current-speed = <1000000>;
	status = "okay";
};

/* ── GPIO banks ───────────────────────────────────────────────────────────── */

&gpioa { status = "okay"; };
&gpiob { status = "okay"; };
&gpioc { status = "okay"; };
&gpiod { status = "okay"; };

/* ── Flash partitions ─────────────────────────────────────────────────────── */

/*
 * The Bitcraze CF2.1 brushless bootloader occupies the first 16 KB
 * (0x08000000–0x08003FFF).  cfloader/crazyradio2 writes application images
 * starting at 0x08004000 (start_page=16 in the bootloader's flash info).
 *
 * Confirmed from the CF2.1 firmware linker script: FLASH ORIGIN = 0x8004000
 * and _estack = 0x2001FFFF.  Run "cfloader info" and look for "Start page: 16"
 * to verify.  If "Start page: 64" is reported instead, change partition@4000
 * to partition@10000 and boot_partition size to 0x10000.
 */
&flash0 {
	partitions {
		compatible = "fixed-partitions";
		#address-cells = <1>;
		#size-cells = <1>;

		boot_partition: partition@0 {
			label = "bootloader";
			reg = <0x00000000 0x00004000>;   /* 16 KB Bitcraze bootloader */
			read-only;
		};

		slot0_partition: partition@4000 {
			label = "image-0";
			reg = <0x00004000 0x000FC000>;   /* 1008 KB application */
		};
	};
};
```

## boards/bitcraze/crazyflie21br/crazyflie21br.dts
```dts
/*
 * crazyflie21br.dts — Zephyr board DTS for Bitcraze Crazyflie 2.1 Brushless
 *
 * MCU:   STM32F405RGT6 (Cortex-M4F, 168 MHz, 1 MB flash, 192 KB SRAM)
 * Clock: 8 MHz HSE crystal → PLL (M=8,N=336,P=2,Q=7) → 168 MHz SYSCLK / 48 MHz USB
 *
 * Console: USART3 on PC10 (TX) / PC11 (RX), 115200 baud.
 * Connect a 3.3 V USB-serial adapter: white (adapter RX) → PC10, green (adapter TX) → PC11, GND.
 *
 * Motor PWM and the nRF51 HCI UART are configured in the app overlay
 * (tapestry-os/boards/crazyflie21br/crazyflie21br.overlay).
 */

/dts-v1/;
#include <st/f4/stm32f405Xg.dtsi>
#include <st/f4/stm32f405rgtx-pinctrl.dtsi>
#include <zephyr/dt-bindings/gpio/gpio.h>

/ {
	model = "Bitcraze Crazyflie 2.1 Brushless";
	compatible = "bitcraze,crazyflie21br";

	chosen {
		zephyr,sram           = &sram0;
		zephyr,flash          = &flash0;
		zephyr,ccm            = &ccm0;
		zephyr,code-partition = &slot0_partition;
		zephyr,console        = &usart3;
		zephyr,shell-uart     = &usart3;
	};

	aliases {
		led0 = &status_led;
	};

	/*
	 * PD2 = LED_BLUE_L — M2 arm blue LED, active-high (STM32 sources current).
	 * This is the only STM32-GPIO-controlled LED visible to the user on the
	 * CF2.1 brushless; there are no LEDs on the main board.
	 *
	 * Main board net names for reference (not routed to visible LEDs):
	 *   LED_RED_L=PC0, LED_GREEN_L=PC1, LED_GREEN_R=PC2, LED_RED_R=PC3.
	 */
	leds {
		compatible = "gpio-leds";
		status_led: status_led_0 {
			gpios = <&gpiod 2 GPIO_ACTIVE_HIGH>;
			label = "M2 Blue LED";
		};
	};
};

/* ── Clocks ──────────────────────────────────────────────────────────────── */

&clk_hse {
	/*
	 * 8 MHz HSE crystal (not bypassed) — matches the stock Bitcraze
	 * firmware's HSE_VALUE=8000000 / PLL_M=8 (system_stm32f4xx.c), which
	 * also explicitly clears HSEBYP before enabling HSE.  No "TCXO"/"40 MHz"
	 * reference exists anywhere in that firmware tree; the previous 40 MHz
	 * bypass assumption produced a ~0.2 MHz PLL input, far outside the
	 * STM32F405's valid 0.95-2.1 MHz PLL input range.
	 *
	 * PLL: VCO_in = 8/8 = 1 MHz, VCO_out = 336 MHz
	 *      SYSCLK = 336/2 = 168 MHz, USB = 336/7 = 48 MHz
	 */
	clock-frequency = <DT_FREQ_M(8)>;
	status = "okay";
};

&pll {
	div-m = <8>;
	mul-n = <336>;
	div-p = <2>;
	div-q = <7>;
	clocks = <&clk_hse>;
	status = "okay";
};

&rcc {
	clocks        = <&pll>;
	clock-frequency = <DT_FREQ_M(168)>;
	ahb-prescaler = <1>;
	/* Canonical STM32F405 168 MHz tree (matches stock firmware): APB1 max
	 * 42 MHz needs /4, APB2 max 84 MHz needs /2.  Earlier debugging set
	 * these to <1>/<1> while chasing a clock mismatch that turned out to
	 * be the wrong &clk_hse frequency (see &clk_hse comment) — with that
	 * fixed, the textbook /4 and /2 prescalers should produce correct
	 * UART baud rates again. */
	apb1-prescaler = <4>;   /* APB1 = 168/4 = 42 MHz */
	apb2-prescaler = <2>;   /* APB2 = 168/2 = 84 MHz */
};

/* ── Console UART ────────────────────────────────────────────────────────── */

/*
 * USART3 on PC10 (TX) / PC11 (RX), 115200 baud.
 * Connect a 3.3 V USB-serial adapter: white (RX) → PC10, green (TX) → PC11, GND.
 */
&usart3 {
	pinctrl-0 = <&usart3_tx_pc10 &usart3_rx_pc11>;
	pinctrl-names = "default";
	current-speed = <115200>;
	status = "okay";
};

&usart2 {
	pinctrl-0 = <&usart2_tx_pa2 &usart2_rx_pa3>;
	pinctrl-names = "default";
	current-speed = <115200>;
	status = "okay";
};

/* ── nRF51822 BLE radio co-processor ────────────────────────────────────── */

/*
 * The nRF51822 is connected to the STM32F405 via USART6 (PC6/PC7).
 * PC6 = STM32 TX (NRF_RX net), PC7 = STM32 RX (NRF_TX net).
 * Pin assignment verified against CF2.1 Brushless schematic Rev.G.
 *
 * Enabled here so that all builds (app and tests) can use USART6 for
 * CRTP syslink console output (cf21_crtp_log.c).  The nRF51 factory
 * firmware forwards CRTP console packets over 2.4 GHz radio to
 * crazyradio2; read_console.py receives them on the host.
 *
 * When the nRF51 is reflashed with HCI firmware for BLE, uncomment
 * CONFIG_BT_HCI_UART in tapestry-scr-hw/boards/crazyflie21br.conf and
 * disable cf21_crtp_log.c (the two uses of USART6 are mutually exclusive).
 */
/* Raise PC6 (USART6_TX) slew rate from Zephyr's default 2 MHz low-speed to
 * very-high-speed (100 MHz).  The CF firmware uses GPIO_Speed_25MHz; without
 * at least medium speed, the 1 Mbps USART transitions take ~250 ns (25% of a
 * bit period) and the nRF51 cannot reliably detect the start bit. */
&usart6_tx_pc6 {
	slew-rate = "very-high-speed";
};

&usart6 {
	pinctrl-0 = <&usart6_tx_pc6 &usart6_rx_pc7>;
	pinctrl-names = "default";
	current-speed = <1000000>;
	status = "okay";
};

/* ── GPIO banks ───────────────────────────────────────────────────────────── */

&gpioa { status = "okay"; };
&gpiob { status = "okay"; };
&gpioc { status = "okay"; };
&gpiod { status = "okay"; };

/* ── Flash partitions ─────────────────────────────────────────────────────── */

/*
 * The Bitcraze CF2.1 brushless bootloader occupies the first 16 KB
 * (0x08000000–0x08003FFF).  cfloader/crazyradio2 writes application images
 * starting at 0x08004000 (start_page=16 in the bootloader's flash info).
 *
 * Confirmed from the CF2.1 firmware linker script: FLASH ORIGIN = 0x8004000
 * and _estack = 0x2001FFFF.  Run "cfloader info" and look for "Start page: 16"
 * to verify.  If "Start page: 64" is reported instead, change partition@4000
 * to partition@10000 and boot_partition size to 0x10000.
 */
&flash0 {
	partitions {
		compatible = "fixed-partitions";
		#address-cells = <1>;
		#size-cells = <1>;

		boot_partition: partition@0 {
			label = "bootloader";
			reg = <0x00000000 0x00004000>;   /* 16 KB Bitcraze bootloader */
			read-only;
		};

		slot0_partition: partition@4000 {
			label = "image-0";
			reg = <0x00004000 0x000FC000>;   /* 1008 KB application */
		};
	};
};
```

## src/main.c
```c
/*
 * main.c — Tapestry hardware element (L4 CSM + L5 SCR; L6 BSE ticks but its
 * output is not yet consumed here — see the NOTE below)
 *
 * One source file builds for all board targets.  Transport and actuation
 * are selected by the build system (see CMakeLists.txt):
 *
 *   BBC micro:bit V2  — BLE gossip, Cutebot motors/LEDs, serial telemetry
 *   EK-RA8D1          — UDP gossip, no actuators, UDP telemetry
 *   ESP-WROVER-KIT    — BLE + UDP gossip bridge, no actuators, UDP telemetry
 *
 * Startup sequence:
 *   tapestry_runtime_init() — substrate, transport, L4/L5/L6/L7 init
 *   choreo_submit_goal()    — set swarm goal
 *   main loop               — tick runtime, drive substrate from SCR state
 *
 * L6/L7 actuation: tapestry_runtime_tick() drives L6 each cycle
 * (choreo_tick() fires via the L5 on_tick hook, see runtime.c), and the
 * movement loop below reads choreo_get_directive() to decide whether to
 * move at all — MOVE_TO_POINT / MAINTAIN_SPRING move, IDLE / HOLD stop.
 * SCR quorum still gates safety (no motion below HEALTHY) and role still
 * tiers speed.
 *
 * This is deliberately coarse: this reference element never calls
 * tapestry_runtime_update_pos() (no dead-reckoning/heading source on any
 * of its three boards, and two of them — EK-RA8D1, ESP-WROVER-KIT — have
 * no actuators at all), so there is no closed-loop point tracking here,
 * only a move/hold decision driven by directive type.
 * examples/cf21bl-formation/src/main.c is the reference for an element
 * that actually tracks a commanded point.
 */

#include <zephyr/kernel.h>
#include <zephyr/logging/log.h>
#include <tapestry/runtime.h>
#include <tapestry/substrate.h>
#include <tapestry/choreo.h>

LOG_MODULE_REGISTER(element, LOG_LEVEL_INF);

/* Fixed logical positions (units in a 100×100 world). */
static const float ELEMENT_POS_X[] = { 10.0f, 50.0f, 30.0f, 70.0f, 90.0f };
static const float ELEMENT_POS_Y[] = { 10.0f, 50.0f, 80.0f, 20.0f, 60.0f };

/* ── Entry point ──────────────────────────────────────────────────────────── */

int main(void)
{
    const element_id_t element_id = (element_id_t)CONFIG_TAPESTRY_ELEMENT_ID;

    tapestry_runtime_config_t cfg = {
        .self_id          = element_id,
        .pos_x            = ELEMENT_POS_X[element_id],
        .pos_y            = ELEMENT_POS_Y[element_id],
        .consistency_bias = 0.0f,
        .quorum_min       = (uint8_t)CONFIG_TAPESTRY_QUORUM_MIN,
        .quorum_target    = (uint8_t)CONFIG_TAPESTRY_QUORUM_TARGET,
    };

    LOG_INF("element %u starting  pos=(%.1f, %.1f)  quorum=%d/%d",
            (unsigned)element_id,
            (double)cfg.pos_x, (double)cfg.pos_y,
            CONFIG_TAPESTRY_QUORUM_MIN, CONFIG_TAPESTRY_QUORUM_TARGET);

    if (tapestry_runtime_init(&cfg) != 0) {
        return -1;
    }

    choreo_goal_t goal = {
        .type   = CHOREO_GOAL_FORM,
        .target = { .x = 50.0f, .y = 50.0f },
        .radius = 30.0f,
        .shape  = TAPESTRY_BSE_SHAPE_CIRCLE,
    };
    choreo_submit_goal(&goal);
    LOG_INF("element %u ready — default goal: FORM circle r=30 @ (50,50)",
            (unsigned)element_id);

    /* ── Main loop ─────────────────────────────────────────────────────── */

    while (true) {
        tapestry_runtime_tick();

        const scr_state_t *scr = tapestry_runtime_scr();

        substrate_signal_t sig;
        if      (scr->quorum_state == SCR_QUORUM_HEALTHY)  sig = SUBSTRATE_SIGNAL_ACTIVE;
        else if (scr->quorum_state == SCR_QUORUM_DEGRADED) sig = SUBSTRATE_SIGNAL_DEGRADED;
        else                                                sig = SUBSTRATE_SIGNAL_FAILED;
        substrate_set_signal(sig);

        const tapestry_bse_directive_t *directive = choreo_get_directive();

        substrate_twist_t twist = {0};
        if (scr->quorum_state == SCR_QUORUM_HEALTHY &&
            (directive->type == TAPESTRY_BSE_DIRECTIVE_MOVE_TO_POINT ||
             directive->type == TAPESTRY_BSE_DIRECTIVE_MAINTAIN_SPRING)) {
            twist.linear.x = (scr->role == SCR_ROLE_LEADER) ? 0.7f : 0.5f;
        }
        substrate_move(&twist);

        k_msleep(WM_CYCLE_MS);
    }

    return 0;
}
```

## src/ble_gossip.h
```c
/*
 * ble_gossip.h — optional BLE advertising/scanning gossip transport
 *
 * On boards that have CONFIG_BT=y (currently: ESP32-WROVER-KIT), this layer
 * runs alongside the UDP comms layer so the element participates in both the
 * LAN swarm (via UDP) and the BLE swarm (via advertising).
 *
 * The wire format is shared across all board targets so a micro:bit element
 * interoperates directly with the ESP32 element without any bridge process.
 */

#ifndef TAPESTRY_BLE_GOSSIP_H
#define TAPESTRY_BLE_GOSSIP_H

#ifdef CONFIG_BT

#include <tapestry/csm.h>
#include "sim_protocol.h"

#ifdef __cplusplus
extern "C" {
#endif

/* Enable BT, start passive scanning, begin non-connectable advertising.
 * Returns 0 on success, negative errno on failure. */
int ble_gossip_init(void);

/* Update the BLE advertising payload with own_state. */
void ble_gossip_send(const element_state_t *own_state);

/* Drain received BLE gossip frames into wm.  Skips own_id frames.
 * Returns the number of frames processed. */
int ble_gossip_drain(world_model_t *wm, element_id_t own_id);

/* ── Auto-ID discovery ───────────────────────────────────────────────────── */

/* Advertise a discovery beacon (gossip packet with id=ELEMENT_ID_INVALID,
 * hardware nonce in update_seq).  Call during the boot window before
 * element_id is known.  ble_gossip_send() switches back to normal gossip. */
void ble_gossip_advertise_nonce(uint32_t nonce);

/* Drain hardware nonces collected from co-booting peers into out[0..max-1].
 * Returns count written. */
int ble_gossip_drain_nonces(uint32_t *out, int max);

/* Drain the gossip queue without a world model, marking which element IDs
 * have been seen advertising.  claimed_out must be a zeroed bool array of
 * at least max_id elements.  Returns frames drained. */
int ble_gossip_drain_claimed(bool *claimed_out, int max_id);

#ifdef __cplusplus
}
#endif

#endif /* CONFIG_BT */
#endif /* TAPESTRY_BLE_GOSSIP_H */
```

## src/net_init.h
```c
/*
 * net_init.h — network bring-up for Tapestry hardware elements
 *
 * Provides a single blocking call that acquires an IPv4 address before
 * the main gossip loop starts.  The implementation selects the correct
 * path at compile time:
 *
 *   CONFIG_WIFI set   → join the AP configured by TAPESTRY_WIFI_SSID/PSK,
 *                        then wait for DHCP to assign an address.
 *   CONFIG_WIFI unset → start DHCPv4 on the default interface (Ethernet)
 *                        and wait for an address to be assigned.
 */

#ifndef TAPESTRY_NET_INIT_H
#define TAPESTRY_NET_INIT_H

/*
 * net_connect — bring up the network and acquire an IPv4 address.
 *
 * Blocks until an address is obtained.
 * Returns 0 on success, -1 on unrecoverable error (logged).
 */
int net_connect(void);

#endif /* TAPESTRY_NET_INIT_H */
```
